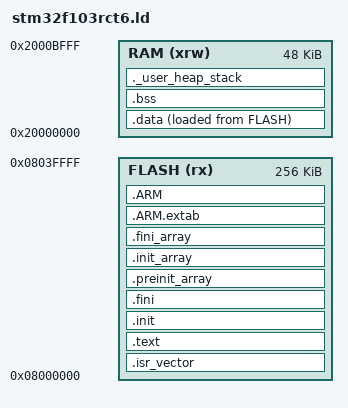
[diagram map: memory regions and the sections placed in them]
ENTRY(Reset_Handler)

_estack = ORIGIN(RAM) + LENGTH(RAM);

MEMORY
{
  FLASH (rx)  : ORIGIN = 0x08000000, LENGTH = 256K
  RAM   (xrw) : ORIGIN = 0x20000000, LENGTH = 48K
}

SECTIONS
{
  .isr_vector :
  {
    . = ALIGN(4);
    KEEP(*(.isr_vector))
    . = ALIGN(4);
  } >FLASH

  .text :
  {
    . = ALIGN(4);
    *(.text)
    *(.text*)
    *(.rodata)
    *(.rodata*)
    *(.glue_7)
    *(.glue_7t)
    . = ALIGN(4);
    _etext = .;
  } >FLASH

  /* nano libc's __libc_init_array() calls _init() before main().  With
   * --gc-sections, the matching crtn return sequence is discarded unless the
   * complete init/fini input sections are explicitly retained.  Retaining
   * these sections also provides valid empty constructor-array boundaries. */
  .init :
  {
    KEEP(*(.init))
  } >FLASH

  .fini :
  {
    KEEP(*(.fini))
  } >FLASH

  .preinit_array :
  {
    PROVIDE_HIDDEN(__preinit_array_start = .);
    KEEP(*(.preinit_array*))
    PROVIDE_HIDDEN(__preinit_array_end = .);
  } >FLASH

  .init_array :
  {
    PROVIDE_HIDDEN(__init_array_start = .);
    KEEP(*(SORT(.init_array.*)))
    KEEP(*(.init_array*))
    PROVIDE_HIDDEN(__init_array_end = .);
  } >FLASH

  .fini_array :
  {
    PROVIDE_HIDDEN(__fini_array_start = .);
    KEEP(*(SORT(.fini_array.*)))
    KEEP(*(.fini_array*))
    PROVIDE_HIDDEN(__fini_array_end = .);
  } >FLASH

  .ARM.extab : { *(.ARM.extab* .gnu.linkonce.armextab.*) } >FLASH
  .ARM :
  {
    __exidx_start = .;
    *(.ARM.exidx*)
    __exidx_end = .;
  } >FLASH

  _sidata = LOADADDR(.data);
  .data :
  {
    . = ALIGN(4);
    _sdata = .;
    *(.data)
    *(.data*)
    . = ALIGN(4);
    _edata = .;
  } >RAM AT> FLASH

  .bss :
  {
    . = ALIGN(4);
    _sbss = .;
    *(.bss)
    *(.bss*)
    *(COMMON)
    . = ALIGN(4);
    _ebss = .;
    end = .;
    _end = .;
  } >RAM

  ._user_heap_stack :
  {
    . = ALIGN(8);
    . = . + 0x400;
    . = . + 0x800;
    . = ALIGN(8);
  } >RAM
}
